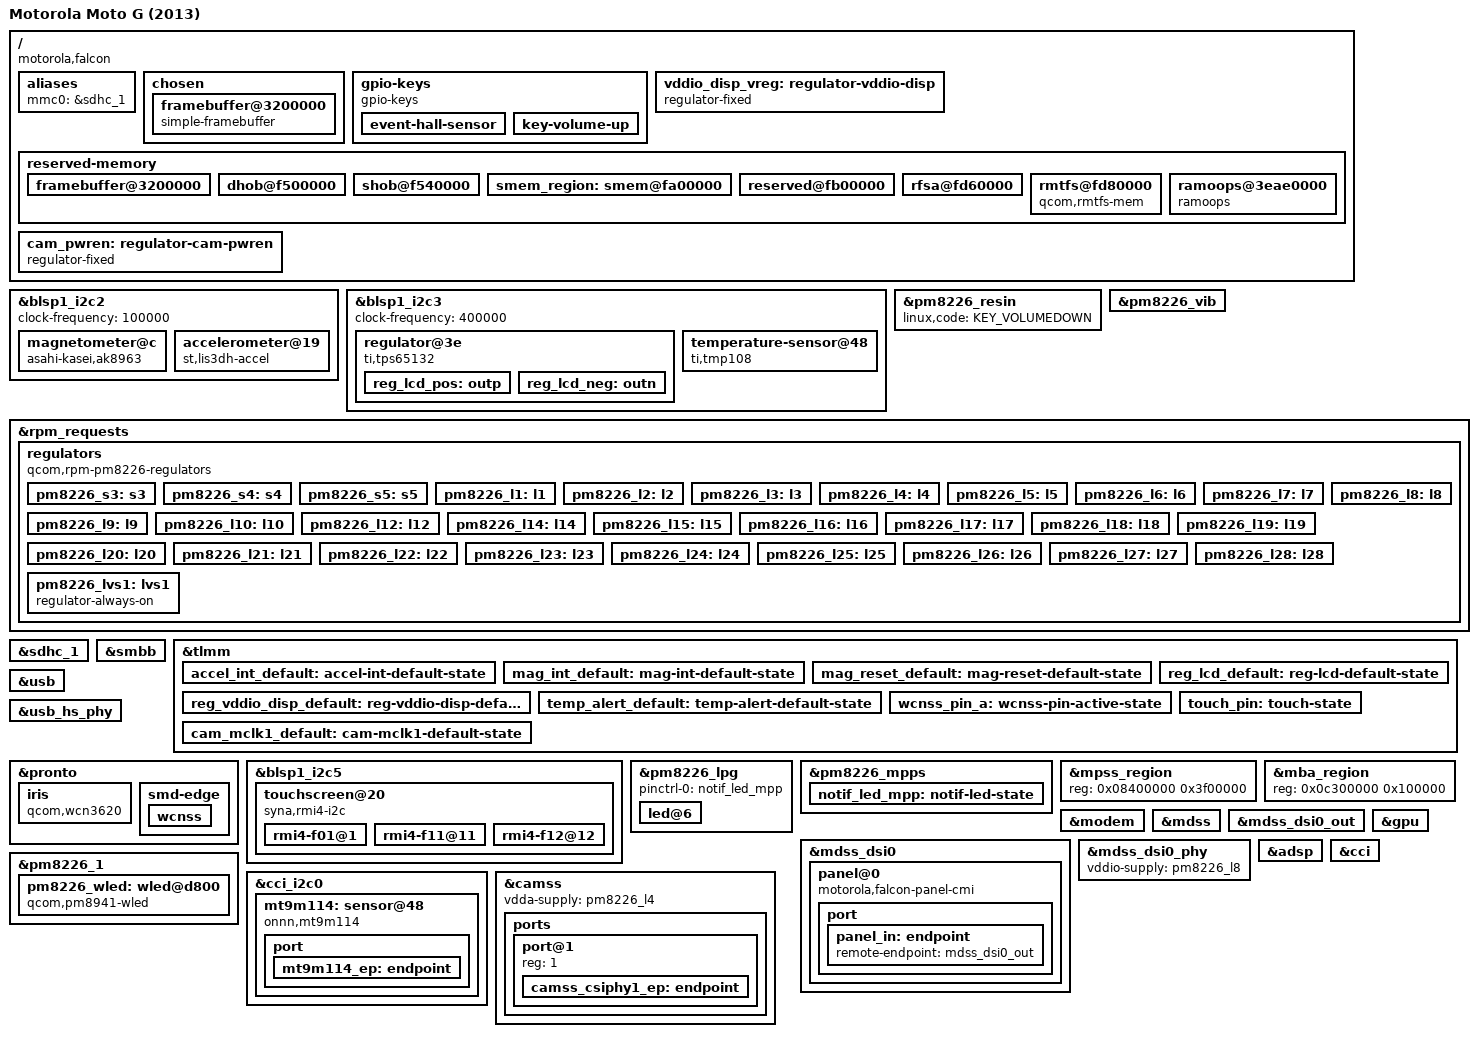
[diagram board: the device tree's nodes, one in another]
// SPDX-License-Identifier: BSD-3-Clause

/dts-v1/;

#include <dt-bindings/leds/common.h>
#include "qcom-msm8226.dtsi"
#include "pm8226.dtsi"

/delete-node/ &smem_region;

/ {
	model = "Motorola Moto G (2013)";
	compatible = "motorola,falcon", "qcom,msm8226";
	chassis-type = "handset";

	aliases {
		mmc0 = &sdhc_1;
	};

	chosen {
		#address-cells = <1>;
		#size-cells = <1>;
		ranges;

		framebuffer@3200000 {
			compatible = "simple-framebuffer";
			reg = <0x03200000 0x800000>;
			width = <720>;
			height = <1280>;
			stride = <(720 * 3)>;
			format = "r8g8b8";
			vsp-supply = <&reg_lcd_pos>;
			vsn-supply = <&reg_lcd_neg>;
			vddio-supply = <&vddio_disp_vreg>;
			/* simplefb mantido: o msm assume depois. BYTE0/PCLK0 precisam estar aqui;
			 * sem simplefb o msm trava ao ler o PLL da DSI. */
			clocks = <&mmcc MDSS_AHB_CLK>,
				 <&mmcc MDSS_AXI_CLK>,
				 <&mmcc MDSS_BYTE0_CLK>,
				 <&mmcc MDSS_ESC0_CLK>,
				 <&mmcc MDSS_MDP_CLK>,
				 <&mmcc MMSS_MISC_AHB_CLK>,
				 <&mmcc MDSS_PCLK0_CLK>,
				 <&mmcc MDSS_VSYNC_CLK>;
			power-domains = <&mmcc MDSS_GDSC>;
		};
	};

	gpio-keys {
		compatible = "gpio-keys";

		event-hall-sensor {
			label = "Hall Effect Sensor";
			gpios = <&tlmm 51 GPIO_ACTIVE_LOW>;
			linux,input-type = <EV_SW>;
			linux,code = <SW_LID>;
			linux,can-disable;
		};

		key-volume-up {
			label = "Volume Up";
			gpios = <&tlmm 106 GPIO_ACTIVE_LOW>;
			linux,code = <KEY_VOLUMEUP>;
			debounce-interval = <15>;
		};
	};

	/* TI TPS22902 */
	vddio_disp_vreg: regulator-vddio-disp {
		compatible = "regulator-fixed";
		regulator-name = "vddio_disp";
		regulator-min-microvolt = <1800000>;
		regulator-max-microvolt = <1800000>;
		gpio = <&tlmm 34 GPIO_ACTIVE_HIGH>;
		vin-supply = <&pm8226_l8>;
		startup-delay-us = <300>;
		enable-active-high;
		regulator-boot-on;
	};

	reserved-memory {
		#address-cells = <1>;
		#size-cells = <1>;
		ranges;

		framebuffer@3200000 {
			reg = <0x03200000 0x800000>;
			no-map;
		};

		dhob@f500000 {
			reg = <0x0f500000 0x40000>;
			no-map;
		};

		shob@f540000 {
			reg = <0x0f540000 0x2000>;
			no-map;
		};

		smem_region: smem@fa00000 {
			reg = <0x0fa00000 0x100000>;
			no-map;
		};

		/* Actually <0x0fa00000 0x500000>, but first 100000 is smem */
		reserved@fb00000 {
			reg = <0x0fb00000 0x260000>;
			no-map;
		};

		/* downstream: rfsa_dsp/rfsa_mdm e rmtfs_sharedmem (qcom,sharedmem-uio) */
		rfsa@fd60000 {
			reg = <0x0fd60000 0x20000>;
			no-map;
		};

		rmtfs@fd80000 {
			compatible = "qcom,rmtfs-mem";
			reg = <0x0fd80000 0x180000>;
			no-map;

			qcom,client-id = <1>;
		};
	};
};

&blsp1_i2c2 {
	clock-frequency = <100000>;
	status = "okay";

	magnetometer@c {
		compatible = "asahi-kasei,ak8963";
		reg = <0xc>;
		interrupts-extended = <&tlmm 66 IRQ_TYPE_EDGE_FALLING>;
		reset-gpios = <&tlmm 62 GPIO_ACTIVE_LOW>;
		vdd-supply = <&pm8226_l19>;
		vid-supply = <&pm8226_lvs1>;
		pinctrl-0 = <&mag_int_default &mag_reset_default>;
		pinctrl-names = "default";
	};

	accelerometer@19 {
		compatible = "st,lis3dh-accel";
		reg = <0x19>;
		interrupts-extended = <&tlmm 63 IRQ_TYPE_EDGE_FALLING>;
		vdd-supply = <&pm8226_l19>;
		vddio-supply = <&pm8226_lvs1>;
		pinctrl-0 = <&accel_int_default>;
		pinctrl-names = "default";
		mount-matrix = "0", "1", "0",
			       "1", "0", "0",
			       "0", "0", "-1";
		st,drdy-int-pin = <1>;
	};
};

&blsp1_i2c3 {
	clock-frequency = <400000>;
	status = "okay";

	regulator@3e {
		compatible = "ti,tps65132";
		reg = <0x3e>;
		pinctrl-0 = <&reg_lcd_default>;
		pinctrl-names = "default";

		reg_lcd_pos: outp {
			regulator-name = "outp";
			regulator-min-microvolt = <5400000>;
			regulator-max-microvolt = <5400000>;
			regulator-active-discharge = <1>;
			regulator-boot-on;
			enable-gpios = <&tlmm 31 GPIO_ACTIVE_HIGH>;
		};

		reg_lcd_neg: outn {
			regulator-name = "outn";
			regulator-min-microvolt = <5400000>;
			regulator-max-microvolt = <5400000>;
			regulator-active-discharge = <1>;
			regulator-boot-on;
			enable-gpios = <&tlmm 33 GPIO_ACTIVE_HIGH>;
		};
	};

	temperature-sensor@48 {
		compatible = "ti,tmp108";
		reg = <0x48>;
		interrupts-extended = <&tlmm 13 IRQ_TYPE_LEVEL_LOW>;
		pinctrl-0 = <&temp_alert_default>;
		pinctrl-names = "default";
		#thermal-sensor-cells = <0>;
	};
};

&pm8226_resin {
	linux,code = <KEY_VOLUMEDOWN>;
	status = "okay";
};

&pm8226_vib {
	status = "okay";
};

&rpm_requests {
	regulators {
		compatible = "qcom,rpm-pm8226-regulators";

		pm8226_s3: s3 {
			regulator-min-microvolt = <1200000>;
			regulator-max-microvolt = <1300000>;
		};

		pm8226_s4: s4 {
			regulator-min-microvolt = <1800000>;
			regulator-max-microvolt = <2200000>;
		};

		pm8226_s5: s5 {
			regulator-min-microvolt = <1150000>;
			regulator-max-microvolt = <1150000>;
		};

		pm8226_l1: l1 {
			regulator-min-microvolt = <1225000>;
			regulator-max-microvolt = <1225000>;
		};

		pm8226_l2: l2 {
			regulator-min-microvolt = <1200000>;
			regulator-max-microvolt = <1200000>;
		};

		pm8226_l3: l3 {
			regulator-min-microvolt = <750000>;
			regulator-max-microvolt = <1337500>;
		};

		pm8226_l4: l4 {
			regulator-min-microvolt = <1200000>;
			regulator-max-microvolt = <1200000>;
		};

		pm8226_l5: l5 {
			regulator-min-microvolt = <1200000>;
			regulator-max-microvolt = <1200000>;
		};

		pm8226_l6: l6 {
			regulator-min-microvolt = <1800000>;
			regulator-max-microvolt = <1800000>;
			regulator-allow-set-load;
		};

		pm8226_l7: l7 {
			regulator-min-microvolt = <1850000>;
			regulator-max-microvolt = <1850000>;
		};

		pm8226_l8: l8 {
			regulator-min-microvolt = <1800000>;
			regulator-max-microvolt = <1800000>;
			/* alimenta o PLL do Pronto (vdd_pronto_pll no downstream) */
			regulator-always-on;
		};

		pm8226_l9: l9 {
			regulator-min-microvolt = <2050000>;
			regulator-max-microvolt = <2050000>;
		};

		pm8226_l10: l10 {
			regulator-min-microvolt = <1800000>;
			regulator-max-microvolt = <1800000>;
		};

		pm8226_l12: l12 {
			regulator-min-microvolt = <1800000>;
			regulator-max-microvolt = <1800000>;
		};

		pm8226_l14: l14 {
			regulator-min-microvolt = <2750000>;
			regulator-max-microvolt = <2750000>;
		};

		pm8226_l15: l15 {
			regulator-min-microvolt = <2800000>;
			regulator-max-microvolt = <2800000>;
		};

		pm8226_l16: l16 {
			regulator-min-microvolt = <3000000>;
			regulator-max-microvolt = <3350000>;
		};

		pm8226_l17: l17 {
			regulator-min-microvolt = <2950000>;
			regulator-max-microvolt = <2950000>;
		};

		pm8226_l18: l18 {
			regulator-min-microvolt = <2950000>;
			regulator-max-microvolt = <2950000>;
		};

		pm8226_l19: l19 {
			regulator-min-microvolt = <2850000>;
			regulator-max-microvolt = <2850000>;
		};

		pm8226_l20: l20 {
			regulator-min-microvolt = <3075000>;
			regulator-max-microvolt = <3075000>;
		};

		pm8226_l21: l21 {
			regulator-min-microvolt = <1800000>;
			regulator-max-microvolt = <2950000>;
			regulator-allow-set-load;
		};

		pm8226_l22: l22 {
			regulator-min-microvolt = <1800000>;
			regulator-max-microvolt = <2950000>;
		};

		pm8226_l23: l23 {
			regulator-min-microvolt = <1800000>;
			regulator-max-microvolt = <2950000>;
		};

		pm8226_l24: l24 {
			regulator-min-microvolt = <1300000>;
			regulator-max-microvolt = <1350000>;
		};

		pm8226_l25: l25 {
			regulator-min-microvolt = <1775000>;
			regulator-max-microvolt = <2125000>;
		};

		pm8226_l26: l26 {
			regulator-min-microvolt = <1225000>;
			regulator-max-microvolt = <1225000>;
		};

		pm8226_l27: l27 {
			regulator-min-microvolt = <2050000>;
			regulator-max-microvolt = <2050000>;
		};

		pm8226_l28: l28 {
			regulator-min-microvolt = <3100000>;
			regulator-max-microvolt = <3400000>;
			regulator-boot-on;
		};

		pm8226_lvs1: lvs1 {
			regulator-always-on;
		};
	};
};

&sdhc_1 {
	/* Sem HS200/SDR104/DDR50: a sintonia (tuning) do HS200 falhava e o eMMC dava erro de
	 * gravação até o ext4 ficar somente leitura. Em HS (52 MHz) não há sintonia. */
	sdhci-caps-mask = <0x7 0x0>;
	vmmc-supply = <&pm8226_l17>;
	vqmmc-supply = <&pm8226_l6>;

	bus-width = <8>;
	non-removable;

	status = "okay";
};

&smbb {
	qcom,fast-charge-safe-current = <2000000>;
	qcom,fast-charge-current-limit = <1900000>;
	qcom,fast-charge-safe-voltage = <4400000>;
	qcom,minimum-input-voltage = <4300000>;

	status = "okay";
};

&tlmm {
	accel_int_default: accel-int-default-state {
		pins = "gpio63";
		function = "gpio";
		drive-strength = <2>;
		bias-disable;
		output-disable;
	};

	mag_int_default: mag-int-default-state {
		pins = "gpio66";
		function = "gpio";
		drive-strength = <2>;
		bias-disable;
		output-disable;
	};

	mag_reset_default: mag-reset-default-state {
		pins = "gpio62";
		function = "gpio";
		drive-strength = <2>;
		bias-disable;
		output-high;
	};

	reg_lcd_default: reg-lcd-default-state {
		pins = "gpio31", "gpio33";
		function = "gpio";
		drive-strength = <2>;
		bias-disable;
		output-high;
	};

	reg_vddio_disp_default: reg-vddio-disp-default-state {
		pins = "gpio34";
		function = "gpio";
		drive-strength = <2>;
		bias-disable;
		output-high;
	};

	temp_alert_default: temp-alert-default-state {
		pins = "gpio13";
		function = "gpio";
		drive-strength = <2>;
		bias-disable;
		output-disable;
	};
};

&usb {
	extcon = <&smbb>;
	dr_mode = "peripheral";
	status = "okay";
};

&usb_hs_phy {
	extcon = <&smbb>;
	v1p8-supply = <&pm8226_l10>;
	v3p3-supply = <&pm8226_l20>;
};

/* Wi-Fi/Bluetooth (WCN3620 via Pronto), copiado do msm8226-motorola-titan */
&pronto {
	vddmx-supply = <&pm8226_l3>;
	vddpx-supply = <&pm8226_l6>;

	pinctrl-names = "default";
	pinctrl-0 = <&wcnss_pin_a>;

	status = "okay";

	iris {
		compatible = "qcom,wcn3620";
		/* local-bd-address = [XX XX XX XX XX XX];   placeholder: endereço Bluetooth do aparelho, nunca publicar */
		vddxo-supply = <&pm8226_l10>;
		vddrfa-supply = <&pm8226_l24>;
		vddpa-supply = <&pm8226_l16>;
		vdddig-supply = <&pm8226_l24>;
	};

	smd-edge {
		wcnss {
			status = "okay";
		};
	};
};

&tlmm {
	wcnss_pin_a: wcnss-pin-active-state {
		pins = "gpio40", "gpio41", "gpio42", "gpio43", "gpio44";
		function = "wlan";
		drive-strength = <2>;
		bias-pull-up;
	};
};

/* log persistente entre reboots (mesma área do ram_console do Android Motorola) */
/ {
	reserved-memory {
		ramoops@3eae0000 {
			compatible = "ramoops";
			reg = <0x3eae0000 0x20000>;
			record-size = <0x8000>;
			console-size = <0x10000>;
			pmsg-size = <0x0>;
			ftrace-size = <0x0>;
		};
	};
};

/* Touchscreen Synaptics (RMI4), mesma ligação do msm8226-motorola-titan; vdd = l28 (downstream touch_vdd) */
&blsp1_i2c5 {
	status = "okay";

	touchscreen@20 {
		compatible = "syna,rmi4-i2c";
		reg = <0x20>;

		interrupts-extended = <&tlmm 17 IRQ_TYPE_LEVEL_LOW>;
		reset-gpios = <&tlmm 16 (GPIO_ACTIVE_HIGH | GPIO_PULL_UP)>;

		vdd-supply = <&pm8226_l28>;
		vio-supply = <&pm8226_lvs1>;

		pinctrl-0 = <&touch_pin>;
		pinctrl-names = "default";

		syna,startup-delay-ms = <100>;

		#address-cells = <1>;
		#size-cells = <0>;

		rmi4-f01@1 {
			reg = <0x1>;
			syna,nosleep-mode = <2>;	/* 2 = nunca dormir: com 1 o controlador cochila e o toque chega ~0,5 s atrasado */
		};

		rmi4-f11@11 {
			reg = <0x11>;
			syna,sensor-type = <1>;
		};

		rmi4-f12@12 {
			reg = <0x12>;
			syna,sensor-type = <1>;
		};
	};
};

&tlmm {
	touch_pin: touch-state {
		pins = "gpio17";
		function = "gpio";
		drive-strength = <2>;
		bias-pull-up;
	};
};

/* LED branco de notificação: MPP6 como dreno de corrente, via dtest2, PWM canal 5
 * (downstream: qcom,leds-qpnp-rgb led_mpp_6, source-sel 10, pwm-channel 5;
 *  mesma ligação do qcom-msm8926-htc-memul) */
&pm8226_lpg {
	pinctrl-0 = <&notif_led_mpp>;
	pinctrl-names = "default";
	status = "okay";

	led@6 {
		reg = <6>;
		color = <LED_COLOR_ID_WHITE>;
		function = LED_FUNCTION_INDICATOR;
	};
};

&pm8226_mpps {
	notif_led_mpp: notif-led-state {
		pins = "mpp6";
		function = "sink";
		output-low;
		qcom,dtest = <2>;
	};
};

/* Modem (MSS/Q6v5): faixas tiradas do modem.mdt/mba.mdt do aparelho
 * (downstream: memblock-remove 0x08400000 0x4000000); vdd_mx=l3, vdd_pll=l8 */
&mpss_region {
	reg = <0x08400000 0x3f00000>;
	status = "okay";
};

&mba_region {
	reg = <0x0c300000 0x100000>;
	status = "okay";
};

&modem {
	mx-supply = <&pm8226_l3>;
	pll-supply = <&pm8226_l8>;

	firmware-name = "mba.b00", "modem.mdt";

	status = "okay";
};

/* Tela: painel CMI 720p (vídeo, 2 lanes), driver msm/DRM. Driver do painel: patches/0002 */
&mdss {
	status = "okay";
};

&mdss_dsi0 {
	vdda-supply = <&pm8226_l4>;
	vddio-supply = <&pm8226_l8>;

	panel@0 {
		compatible = "motorola,falcon-panel-cmi";
		reg = <0>;

		/* original: qcom,platform-reset-gpio = <8 25 0> (ativo alto) */
		reset-gpios = <&tlmm 25 GPIO_ACTIVE_HIGH>;
		vddio-supply = <&vddio_disp_vreg>;
		vdd-supply = <&pm8226_l28>;
		vsp-supply = <&reg_lcd_pos>;
		vsn-supply = <&reg_lcd_neg>;

		port {
			panel_in: endpoint {
				remote-endpoint = <&mdss_dsi0_out>;
			};
		};
	};
};

&mdss_dsi0_out {
	remote-endpoint = <&panel_in>;
	data-lanes = <0 1>;
};

&mdss_dsi0_phy {
	vddio-supply = <&pm8226_l8>;
};

/* Luz de fundo: WLED do PM8226 (qcom_wled) */
&pm8226_1 {
	pm8226_wled: wled@d800 {
		compatible = "qcom,pm8941-wled";
		reg = <0xd800>;
		label = "backlight";
		status = "okay";

		default-brightness = <2048>;
		qcom,cs-out;
		qcom,current-limit = <18>;
		qcom,current-boost-limit = <805>;
		qcom,switching-freq = <1600>;
		qcom,ovp = <29>;
		qcom,num-strings = <1>;
	};
};

/* GPU Adreno 305: Mesa freedreno (FD305). Firmware a300_pm4/pfp do linux-firmware */
&gpu {
	status = "okay";
};

/* ADSP (LPASS): firmware extraído do aparelho (não distribuído) */
&adsp {
	firmware-name = "qcom/msm8226/motorola/falcon/adsp.mdt";
	status = "okay";
};

/*
 * Front camera: MT9M114 (onnn,mt9m114) on CCI master 0, address 0x48, wired to
 * CSIPHY 1. Needs patches/camera (CAMSS for MSM8226); without them the camss
 * node simply does not probe.
 *   - MCLK1 on GPIO 27 at 19.2 MHz; link frequency 307.2 MHz on one lane
 *     (19.2 MHz * 32 / (2 * 8) = 38.4 MHz pixel clock, * 8 bits).
 *   - Only L6 (1.8 V) and CAM_PWREN (GPIO 23, 4 ms) power the sensor, as in
 *     the stock kernel; no reset or standby line.
 *   - data-lanes = <0> on the CSIPHY side: LN1 is the clock lane of the
 *     2-phase CSIPHY, data is on LN0 (stock: csi-lane-mask 0x03,
 *     csi-lane-assign 0x4320). With <1> no frame ever reached the CSID.
 */
/ {
	cam_pwren: regulator-cam-pwren {
		compatible = "regulator-fixed";
		regulator-name = "cam_pwren";
		regulator-min-microvolt = <1800000>;
		regulator-max-microvolt = <1800000>;
		gpio = <&tlmm 23 GPIO_ACTIVE_HIGH>;
		enable-active-high;
		startup-delay-us = <4000>;
		vin-supply = <&pm8226_l6>;
	};
};

&tlmm {
	cam_mclk1_default: cam-mclk1-default-state {
		pins = "gpio27";
		function = "cam_mclk1";
		drive-strength = <2>;
		bias-disable;
	};
};

&cci {
	status = "okay";
};

&cci_i2c0 {
	mt9m114: sensor@48 {
		compatible = "onnn,mt9m114";
		reg = <0x48>;

		pinctrl-names = "default";
		pinctrl-0 = <&cam_mclk1_default>;

		clocks = <&mmcc CAMSS_MCLK1_CLK>;
		assigned-clocks = <&mmcc MCLK1_CLK_SRC>;
		assigned-clock-rates = <19200000>;

		vdd-supply = <&pm8226_l6>;
		vddio-supply = <&pm8226_l6>;
		vaa-supply = <&cam_pwren>;

		port {
			mt9m114_ep: endpoint {
				bus-type = <4>; /* MEDIA_BUS_TYPE_CSI2_DPHY */
				data-lanes = <1>;
				link-frequencies = /bits/ 64 <307200000>;
				remote-endpoint = <&camss_csiphy1_ep>;
			};
		};
	};
};

&camss {
	status = "okay";
	vdda-supply = <&pm8226_l4>;

	ports {
		#address-cells = <1>;
		#size-cells = <0>;

		port@1 {
			reg = <1>;

			camss_csiphy1_ep: endpoint {
				bus-type = <4>; /* MEDIA_BUS_TYPE_CSI2_DPHY */
				data-lanes = <0>;
				remote-endpoint = <&mt9m114_ep>;
			};
		};
	};
};
